# AT32F407xx register map
Vendor: Keil; Series: AT32F407; File version: 1.0
CPU: CM4 r0p1, little endian, no MPU, FPU, 4 interrupt priority bits
Registers are 32-bit, read-write, reset 0x0 unless marked. A register's access mark holds for its fields unless they carry their own. Offsets are from the block's base; [hi:lo] are bit positions; {n}, {i} and the like mark numbered series.

## NVIC — Nested Vectored Interrupt Controller
Base 0xE000E000
0x04 ICTR ro — Interrupt Controller Type Register
  [3:0] INTLINESNUM — Total number of interrupt lines in groups
0x100 ISER0 — Interrupt Set-Enable Register
  [31:0] SETENA
0x104 ISER1 — Interrupt Set-Enable Register
  [31:0] SETENA
0x180 ICER0 — Interrupt Clear-Enable Register
  [31:0] CLRENA
0x184 ICER1 — Interrupt Clear-Enable Register
  [31:0] CLRENA
0x200 ISPR0 — Interrupt Set-Pending Register
  [31:0] SETPEND
0x204 ISPR1 — Interrupt Set-Pending Register
  [31:0] SETPEND
0x280 ICPR0 — Interrupt Clear-Pending Register
  [31:0] CLRPEND
0x284 ICPR1 — Interrupt Clear-Pending Register
  [31:0] CLRPEND
0x300 IABR0 ro — Interrupt Active Bit Register
  [31:0] ACTIVE
0x304 IABR1 ro — Interrupt Active Bit Register
  [31:0] ACTIVE
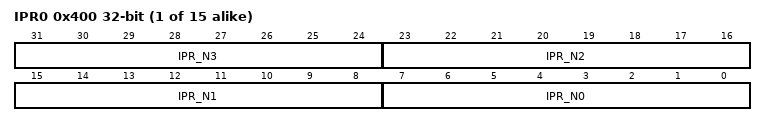
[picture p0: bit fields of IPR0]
{0x400+4i} IPR{i} (i=0..14) — Interrupt Priority Register
  [8n+7:8n] IPR_N{n} (n=0..3)
0xF00 STIR wo — Software Triggered Interrupt Register
  [8:0] INTID — interrupt to be triggered

## USBDEV — Universal serial bus full-speed device interface
Base 0x40005C00
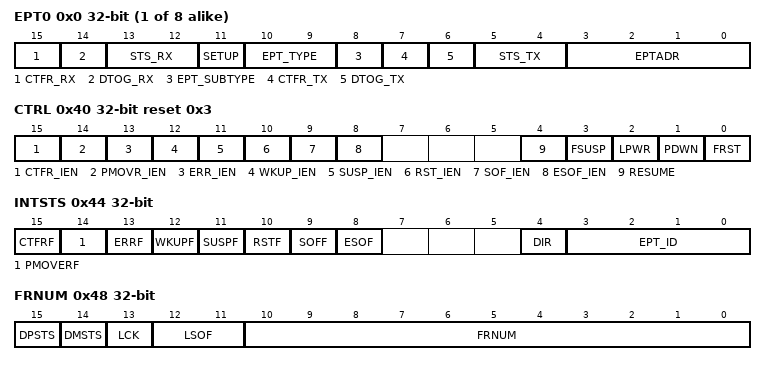
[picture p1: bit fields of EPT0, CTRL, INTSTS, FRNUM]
{0x0+4i} EPT{i} (i=0..7) — endpoint {i} register
  [15] CTFR_RX — Correct transfer for reception
  [14] DTOG_RX — Data Toggle, for reception transfers
  [13:12] STS_RX — Status bits, for reception transfers
  [11] SETUP — Setup transaction completed
  [10:9] EPT_TYPE — Endpoint type
  [8] EPT_SUBTYPE — Endpoint kind
  [7] CTFR_TX — Correct Transfer for transmission
  [6] DTOG_TX — Data Toggle, for transmission transfers
  [5:4] STS_TX — Status bits, for transmission transfers
  [3:0] EPTADR — Endpoint address
0x40 CTRL reset 0x3 — control register
  [15] CTFR_IEN — Correct transfer interrupt mask
  [14] PMOVR_IEN — Packet memory area over / underrun interrupt mask
  [13] ERR_IEN — Error interrupt mask
  [12] WKUP_IEN — Wakeup interrupt mask
  [11] SUSP_IEN — Suspend mode interrupt mask
  [10] RST_IEN — USB reset interrupt mask
  [9] SOF_IEN — Start of frame interrupt mask
  [8] ESOF_IEN — Expected start of frame interrupt mask
  [4] RESUME — Resume request
  [3] FSUSP — Force suspend
  [2] LPWR — Low-power mode
  [1] PDWN — Power down
  [0] FRST — Force USB Reset
0x44 INTSTS — interrupt status register
  [15] CTFRF — Correct transfer
  [14] PMOVERF — Packet memory area over / underrun
  [13] ERRF — Error
  [12] WKUPF — Wakeup
  [11] SUSPF — Suspend mode request
  [10] RSTF — reset request
  [9] SOFF — start of frame
  [8] ESOF — Expected start frame
  [4] DIR — Direction of transaction
  [3:0] EPT_ID — Endpoint Identifier
0x48 FRNUM — frame number register
  [15] DPSTS — Receive data + line status
  [14] DMSTS — Receive data - line status
  [13] LCK — Locked
  [12:11] LSOF — Lost SOF
  [10:0] FRNUM — Frame number
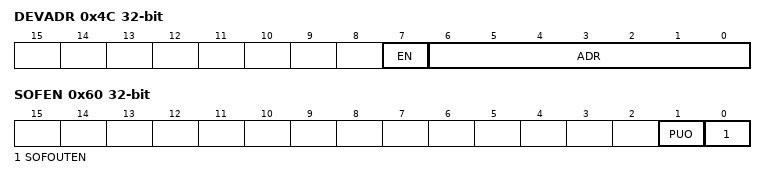
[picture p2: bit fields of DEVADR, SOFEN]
0x4C DEVADR — device address
  [7] EN — Enable function
  [6:0] ADR — Device address
0x50 BUFTBL — Buffer table address
  [15:3] ADR — Buffer table
0x60 SOFEN — SOF control register
  [1] PUO — DP pullup off
  [0] SOFOUTEN — SOF output enable

## ETHERNET_MMC — Ethernet: MAC management counters
Base 0x40028100
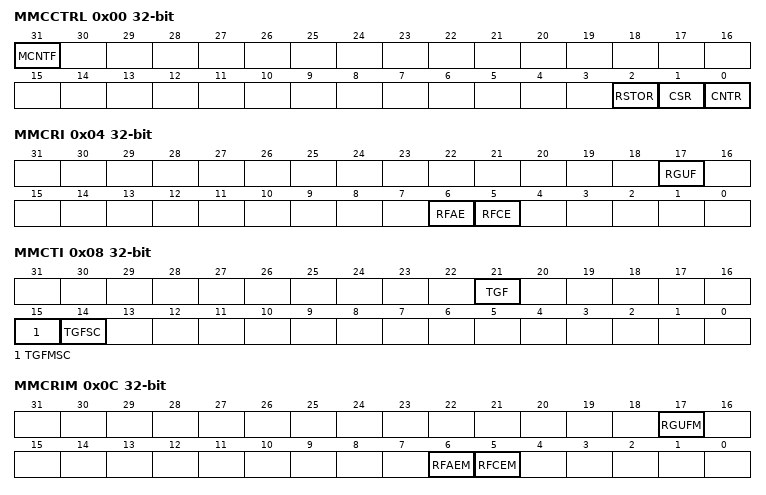
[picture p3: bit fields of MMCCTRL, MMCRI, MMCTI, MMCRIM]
0x00 MMCCTRL — Ethernet MMC control register (ETH_MMCCTRL)
  [31] MCNTF — MMC counter freeze
  [2] RSTOR — Reset on read
  [1] CSR — Counter stop rollover
  [0] CNTR — Counter reset
0x04 MMCRI — Ethernet MMC receive interrupt register (ETH_MMCRI)
  [17] RGUF — Received Good Unicast Frames Status
  [6] RFAE — Received frames alignment error status
  [5] RFCE — Received frames CRC error status
0x08 MMCTI — Ethernet MMC transmit interrupt register (ETH_MMCTI)
  [21] TGF — Transmitted good frames status
  [15] TGFMSC — Transmitted good frames more single collision status
  [14] TGFSC — Transmitted good frames single collision status
0x0C MMCRIM — Ethernet MMC receive interrupt mask register (ETH_MMCRIM)
  [17] RGUFM — Received good unicast frames mask
  [6] RFAEM — Received frames alignment error mask
  [5] RFCEM — Received frame CRC error mask
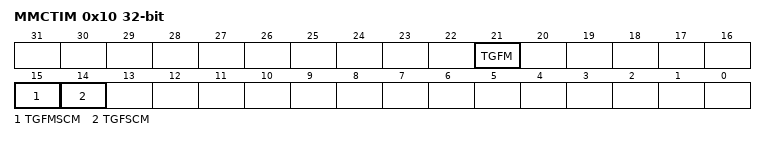
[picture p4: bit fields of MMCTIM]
0x10 MMCTIM — Ethernet MMC transmit interrupt mask register (ETH_MMCTIM)
  [21] TGFM — Transmitted good frames mask
  [15] TGFMSCM — Transmitted good frames more single collision mask
  [14] TGFSCM — Transmitted good frames single collision mask
0x4C MMCTFSCC ro — Ethernet MMC transmitted good frames after a single collision counter
  [31:0] TGFSCC — Transmitted good frames after a single collision counter
0x50 MMCTFMSCC ro — Ethernet MMC transmitted good frames after more than a single collision
  [31:0] TFMSCC — Transmitted good frames after more than a single collision counter
0x68 MMCTFCNT ro — Ethernet MMC transmitted good frames counter register
  [31:0] TFC — Transmitted good frames counter
0x94 MMCRFCECNT ro — Ethernet MMC received frames with CRC error counter register
  [31:0] RFCFC — Received frames with CRC error counter
0x98 MMCRFAECNT ro — Ethernet MMC received frames with alignment error counter register
  [31:0] RFAEC — Received frames with alignment error counter
0xC4 MMCRGUFCNT ro — MMC received good unicast frames counter register
  [31:0] RGUFC — Received good unicast frames counter
